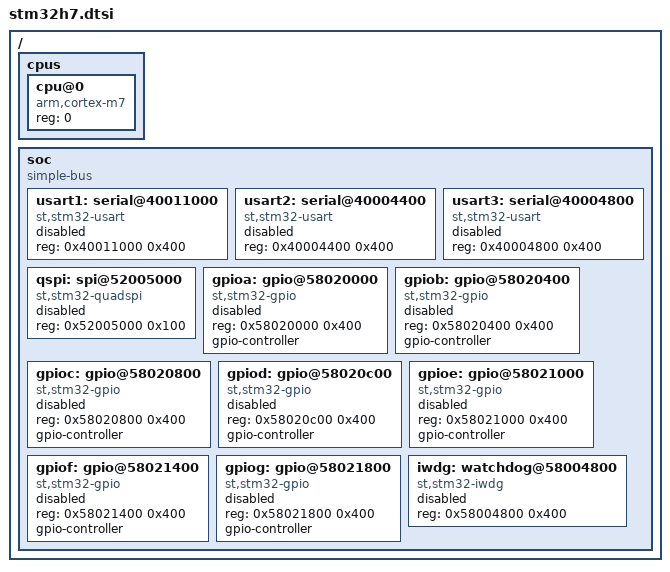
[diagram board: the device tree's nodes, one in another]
/*
 * Shared STM32H7 SoC description for Ark RTOS boards.
 *
 * Same rules as stm32f4.dtsi: only what a board needs is listed, every
 * peripheral starts "disabled", and a board file enables the ones it wires up.
 * Register windows are the Cortex-M7 peripheral addresses from the STM32H7
 * reference manual (RM0433); they are hardware facts, not a memory layout
 * choice, so they belong here and not in config/arkrtos_partition.h.
 *
 * Note the address map differs from the F4 family on purpose: on H7 the
 * APB/AHB peripherals live in the D1/D2/D3 domains starting at 0x40000000,
 * 0x48000000 and 0x58000000 respectively.
 */

/ {
	#address-cells = <1>;
	#size-cells = <1>;

	cpus {
		#address-cells = <1>;
		#size-cells = <0>;

		cpu@0 {
			compatible = "arm,cortex-m7";
			reg = <0>;
		};
	};

	soc {
		compatible = "simple-bus";
		#address-cells = <1>;
		#size-cells = <1>;

		usart1: serial@40011000 {
			compatible = "st,stm32-usart";
			reg = <0x40011000 0x400>;
			status = "disabled";
		};

		usart2: serial@40004400 {
			compatible = "st,stm32-usart";
			reg = <0x40004400 0x400>;
			status = "disabled";
		};

		usart3: serial@40004800 {
			compatible = "st,stm32-usart";
			reg = <0x40004800 0x400>;
			status = "disabled";
		};

		qspi: spi@52005000 {
			compatible = "st,stm32-quadspi";
			reg = <0x52005000 0x100>;
			#address-cells = <1>;
			#size-cells = <0>;
			status = "disabled";
		};

		gpioa: gpio@58020000 {
			compatible = "st,stm32-gpio";
			reg = <0x58020000 0x400>;
			gpio-controller;
			#gpio-cells = <2>;
			status = "disabled";
		};

		gpiob: gpio@58020400 {
			compatible = "st,stm32-gpio";
			reg = <0x58020400 0x400>;
			gpio-controller;
			#gpio-cells = <2>;
			status = "disabled";
		};

		gpioc: gpio@58020800 {
			compatible = "st,stm32-gpio";
			reg = <0x58020800 0x400>;
			gpio-controller;
			#gpio-cells = <2>;
			status = "disabled";
		};

		gpiod: gpio@58020c00 {
			compatible = "st,stm32-gpio";
			reg = <0x58020c00 0x400>;
			gpio-controller;
			#gpio-cells = <2>;
			status = "disabled";
		};

		gpioe: gpio@58021000 {
			compatible = "st,stm32-gpio";
			reg = <0x58021000 0x400>;
			gpio-controller;
			#gpio-cells = <2>;
			status = "disabled";
		};

		gpiof: gpio@58021400 {
			compatible = "st,stm32-gpio";
			reg = <0x58021400 0x400>;
			gpio-controller;
			#gpio-cells = <2>;
			status = "disabled";
		};

		gpiog: gpio@58021800 {
			compatible = "st,stm32-gpio";
			reg = <0x58021800 0x400>;
			gpio-controller;
			#gpio-cells = <2>;
			status = "disabled";
		};

		iwdg: watchdog@58004800 {
			compatible = "st,stm32-iwdg";
			reg = <0x58004800 0x400>;
			status = "disabled";
		};
	};
};
